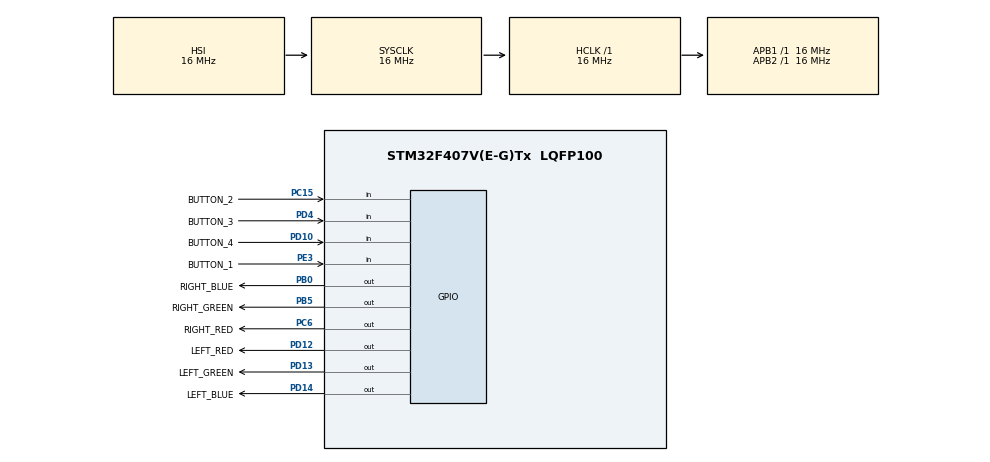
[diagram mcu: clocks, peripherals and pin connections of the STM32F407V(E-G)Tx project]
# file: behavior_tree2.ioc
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Mcu.Family=STM32F4
Mcu.Name=STM32F407V(E-G)Tx
Mcu.Package=LQFP100
NVIC.PriorityGroup=NVIC_PRIORITYGROUP_4
PB0.GPIO_Label=RIGHT_BLUE
PB0.PinState=GPIO_PIN_SET
PB0.Signal=GPIO_Output
PB5.GPIO_Label=RIGHT_GREEN
PB5.PinState=GPIO_PIN_SET
PB5.Signal=GPIO_Output
PC15-OSC32_OUT.GPIO_Label=BUTTON_2
PC15-OSC32_OUT.Signal=GPIO_Input
PC6.GPIO_Label=RIGHT_RED
PC6.PinState=GPIO_PIN_SET
PC6.Signal=GPIO_Output
PD10.GPIO_Label=BUTTON_4
PD10.Signal=GPIO_Input
PD12.GPIO_Label=LEFT_RED
PD12.PinState=GPIO_PIN_SET
PD12.Signal=GPIO_Output
PD13.GPIO_Label=LEFT_GREEN
PD13.PinState=GPIO_PIN_SET
PD13.Signal=GPIO_Output
PD14.GPIO_Label=LEFT_BLUE
PD14.PinState=GPIO_PIN_SET
PD14.Signal=GPIO_Output
PD4.GPIO_Label=BUTTON_3
PD4.Signal=GPIO_Input
PE3.GPIO_Label=BUTTON_1
PE3.Signal=GPIO_Input
ProjectManager.HeapSize=0x200
ProjectManager.StackSize=0x400
ProjectManager.TargetToolchain=STM32CubeIDE
RCC.AHBFreq_Value=16000000
RCC.APB1Freq_Value=16000000
RCC.APB2Freq_Value=16000000
RCC.CortexFreq_Value=16000000
RCC.HSE_VALUE=25000000
RCC.HSI_VALUE=16000000
RCC.LSE_VALUE=32768
RCC.SYSCLKFreq_VALUE=16000000
RCC.VCOOutputFreq_Value=192000000
board=custom

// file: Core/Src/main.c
/* USER CODE BEGIN Header */
/**
  ******************************************************************************
  * @file           : main.c
  * @brief          : Main program body
  ******************************************************************************
  * @attention
  *
  * Copyright (c) 2025 STMicroelectronics.
  * All rights reserved.
  *
  * This software is licensed under terms that can be found in the LICENSE file
  * in the root directory of this software component.
  * If no LICENSE file comes with this software, it is provided AS-IS.
  *
  ******************************************************************************
  */
/* USER CODE END Header */
#include "main.h"

/* USER CODE BEGIN Includes */
#include "common.h"
#include "root.h"
/* USER CODE END Includes */

void SystemClock_Config(void);
static void MX_GPIO_Init(void);

int main(void)
{

  /* MCU Configuration--------------------------------------------------------*/

  /* Reset of all peripherals, Initializes the Flash interface and the Systick. */
  HAL_Init();

  /* Configure the system clock */
  SystemClock_Config();

  /* Initialize all configured peripherals */
  MX_GPIO_Init();

  /* Infinite loop */
  /* USER CODE BEGIN WHILE */

  CompositeNode* root = GET_INSTANCE(root);

  while (1)
  {
	  root->tick(root);
    /* USER CODE END WHILE */

  }
}

void SystemClock_Config(void)
{
  RCC_OscInitTypeDef RCC_OscInitStruct = {0};
  RCC_ClkInitTypeDef RCC_ClkInitStruct = {0};

  /** Configure the main internal regulator output voltage
  */
  __HAL_RCC_PWR_CLK_ENABLE();
  __HAL_PWR_VOLTAGESCALING_CONFIG(PWR_REGULATOR_VOLTAGE_SCALE1);

  /** Initializes the RCC Oscillators according to the specified parameters
  * in the RCC_OscInitTypeDef structure.
  */
  RCC_OscInitStruct.OscillatorType = RCC_OSCILLATORTYPE_HSI;
  RCC_OscInitStruct.HSIState = RCC_HSI_ON;
  RCC_OscInitStruct.HSICalibrationValue = RCC_HSICALIBRATION_DEFAULT;
  RCC_OscInitStruct.PLL.PLLState = RCC_PLL_NONE;
  if (HAL_RCC_OscConfig(&RCC_OscInitStruct) != HAL_OK)
  {
    Error_Handler();
  }

  /** Initializes the CPU, AHB and APB buses clocks
  */
  RCC_ClkInitStruct.ClockType = RCC_CLOCKTYPE_HCLK|RCC_CLOCKTYPE_SYSCLK
                              |RCC_CLOCKTYPE_PCLK1|RCC_CLOCKTYPE_PCLK2;
  RCC_ClkInitStruct.SYSCLKSource = RCC_SYSCLKSOURCE_HSI;
  RCC_ClkInitStruct.AHBCLKDivider = RCC_SYSCLK_DIV1;
  RCC_ClkInitStruct.APB1CLKDivider = RCC_HCLK_DIV1;
  RCC_ClkInitStruct.APB2CLKDivider = RCC_HCLK_DIV1;

  if (HAL_RCC_ClockConfig(&RCC_ClkInitStruct, FLASH_LATENCY_0) != HAL_OK)
  {
    Error_Handler();
  }
}

static void MX_GPIO_Init(void)
{
  GPIO_InitTypeDef GPIO_InitStruct = {0};

  /* GPIO Ports Clock Enable */
  __HAL_RCC_GPIOE_CLK_ENABLE();
  __HAL_RCC_GPIOC_CLK_ENABLE();
  __HAL_RCC_GPIOB_CLK_ENABLE();
  __HAL_RCC_GPIOD_CLK_ENABLE();

  /*Configure GPIO pin Output Level */
  HAL_GPIO_WritePin(GPIOB, RIGHT_BLUE_Pin|RIGHT_GREEN_Pin, GPIO_PIN_SET);

  /*Configure GPIO pin Output Level */
  HAL_GPIO_WritePin(GPIOD, LEFT_RED_Pin|LEFT_GREEN_Pin|LEFT_BLUE_Pin, GPIO_PIN_SET);

  /*Configure GPIO pin Output Level */
  HAL_GPIO_WritePin(RIGHT_RED_GPIO_Port, RIGHT_RED_Pin, GPIO_PIN_SET);

  /*Configure GPIO pin : BUTTON_1_Pin */
  GPIO_InitStruct.Pin = BUTTON_1_Pin;
  GPIO_InitStruct.Mode = GPIO_MODE_INPUT;
  GPIO_InitStruct.Pull = GPIO_NOPULL;
  HAL_GPIO_Init(BUTTON_1_GPIO_Port, &GPIO_InitStruct);

  /*Configure GPIO pin : BUTTON_2_Pin */
  GPIO_InitStruct.Pin = BUTTON_2_Pin;
  GPIO_InitStruct.Mode = GPIO_MODE_INPUT;
  GPIO_InitStruct.Pull = GPIO_NOPULL;
  HAL_GPIO_Init(BUTTON_2_GPIO_Port, &GPIO_InitStruct);

  /*Configure GPIO pins : RIGHT_BLUE_Pin RIGHT_GREEN_Pin */
  GPIO_InitStruct.Pin = RIGHT_BLUE_Pin|RIGHT_GREEN_Pin;
  GPIO_InitStruct.Mode = GPIO_MODE_OUTPUT_PP;
  GPIO_InitStruct.Pull = GPIO_NOPULL;
  GPIO_InitStruct.Speed = GPIO_SPEED_FREQ_LOW;
  HAL_GPIO_Init(GPIOB, &GPIO_InitStruct);

  /*Configure GPIO pins : BUTTON_4_Pin BUTTON_3_Pin */
  GPIO_InitStruct.Pin = BUTTON_4_Pin|BUTTON_3_Pin;
  GPIO_InitStruct.Mode = GPIO_MODE_INPUT;
  GPIO_InitStruct.Pull = GPIO_NOPULL;
  HAL_GPIO_Init(GPIOD, &GPIO_InitStruct);

  /*Configure GPIO pins : LEFT_RED_Pin LEFT_GREEN_Pin LEFT_BLUE_Pin */
  GPIO_InitStruct.Pin = LEFT_RED_Pin|LEFT_GREEN_Pin|LEFT_BLUE_Pin;
  GPIO_InitStruct.Mode = GPIO_MODE_OUTPUT_PP;
  GPIO_InitStruct.Pull = GPIO_NOPULL;
  GPIO_InitStruct.Speed = GPIO_SPEED_FREQ_LOW;
  HAL_GPIO_Init(GPIOD, &GPIO_InitStruct);

  /*Configure GPIO pin : RIGHT_RED_Pin */
  GPIO_InitStruct.Pin = RIGHT_RED_Pin;
  GPIO_InitStruct.Mode = GPIO_MODE_OUTPUT_PP;
  GPIO_InitStruct.Pull = GPIO_NOPULL;
  GPIO_InitStruct.Speed = GPIO_SPEED_FREQ_LOW;
  HAL_GPIO_Init(RIGHT_RED_GPIO_Port, &GPIO_InitStruct);

}

void Error_Handler(void)
{
  __disable_irq();
  while (1)
  {
  }
}
